# R9A02G021 register map
Vendor: Renesas Electronics Corporation; Series: RISC-V; File version: 1.10.00 + 202304131714_CPU
CPU: other r0p0, little endian, no MPU, no FPU, VTOR, 4 interrupt priority bits, 32 interrupts
Registers are 8-bit, read-write, reset 0x0 unless marked. A register's access mark holds for its fields unless they carry their own. Offsets are from the block's base; [hi:lo] are bit positions; {n}, {i} and the like mark numbered series.

## FLCN — Flash I/O Registers
Base 0x407EC000
0x90 DFLCTL — Data Flash Control Register
  [0] DFLEN — Data Flash Access Enable
    0=Access to the data flash is disabled; 1=Access to the data flash is enabled
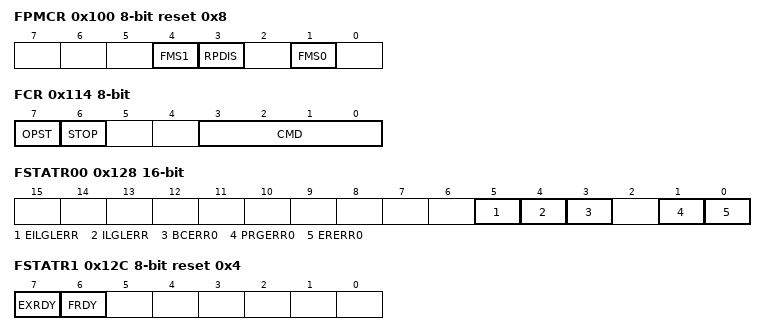
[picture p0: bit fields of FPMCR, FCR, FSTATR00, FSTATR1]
0x100 FPMCR reset 0x8 — Flash P/E Mode Control Register
  [4] FMS1 — Flash Operating Mode Select 1
  [3] RPDIS — Code Flash P/E Disable
    0=Programming of the code flash is enabled; 1=Programming of the code flash is disabled
  [1] FMS0 — Flash Operating Mode Select 0
    0=FMS1 = 0: Read mode FMS1 = 1: Data flash P/E mode; 1=FMS1 = 0: Code flash P/E mode FMS1 = 1: Setting prohibited
0x104 FASR — Flash Area Select Register
  [0] EXS — Extra Area Select
    0=User area or data area; 1=Extra area
0x108 FSARL 16-bit — Flash Processing Start Address Register L
  [15:0] FSARL — Flash Processing Start Address L
0x110 FSARH 16-bit — Flash Processing Start Address Register H
  [15:0] FSARH — Flash Processing Start Address H
0x114 FCR — Flash Control Register
  [7] OPST — Processing Start
    0=Processing stops; 1=Processing starts
  [6] STOP — Forced Processing Stop
  [3:0] CMD — Software Command Setting
    1=Program; 3=Blank check (code flash); 4=Block erase; 6=Chip erase; 11=Blank check (data flash); other=Others (Setting prohibited.)
0x118 FEARL 16-bit — Flash Processing End Address Register L
  [15:0] FEARL — Flash Processing End Address L
0x120 FEARH 16-bit — Flash Processing End Address Register H
  [15:0] FEARH — Flash Processing End Address H
0x124 FRESETR — Flash Reset Register
  [0] FRESET — Software reset of the registers
    0=The registers related to the flash programming are not reset; 1=The registers related to the flash programming are reset
0x128 FSTATR00 16-bit ro — Flash Status Register 0
  [5] EILGLERR — Extra Area Illegal Command Error Flag
    0=No illegal command or illegal access to the extra area is detected; 1=An illegal command or illegal access to the extra area is detected
  [4] ILGLERR — Illegal Command Error Flag
    0=No illegal software command or illegal access is detected; 1=An illegal command or illegal access is detected
  [3] BCERR0 — Blank Check Error Flag 0
    0=Blank checking terminates normally; 1=An error occurs during blank checking
  [1] PRGERR0 — Program Error Flag 0
    0=Programming terminates normally; 1=An error occurs during programming
  [0] ERERR0 — Erase Error Flag 0
    0=Erasure terminates normally; 1=An error occurs during erasure
0x12C FSTATR1 ro reset 0x4 — Flash Status Register 1
  [7] EXRDY — Extra Area Ready Flag
    0=The software command of the FEXCR register is not terminated; 1=The software command of the FEXCR register is terminated
  [6] FRDY — Flash Ready Flag
    0=The software command of the FCR register is not terminated; 1=The software command of the FCR register is terminated
0x130 FWBL0 16-bit — Flash Write Buffer Register L0
  [15:0] WDATA — Flash Write Buffer L0
0x138 FWBH0 16-bit — Flash Write Buffer Register H0
  [15:0] WDATA — Flash Write Buffer H0
0x140 FWBL1 16-bit — Flash Write Buffer Register L1
  [15:0] WDATA — Flash Write Buffer L1 Bits [47:32]
0x144 FWBH1 16-bit — Flash Write Buffer Register H1
  [15:0] WDATA — Flash Write Buffer L1 Bits [63:48]
0x180 FPR reset not defined — Protection Unlock Register
  [7:0] FPR — Protection Unlock
0x184 FPSR ro — Protection Unlock Status Register
  [0] PERR — Protect Error Flag
    0=No error; 1=An error occurs
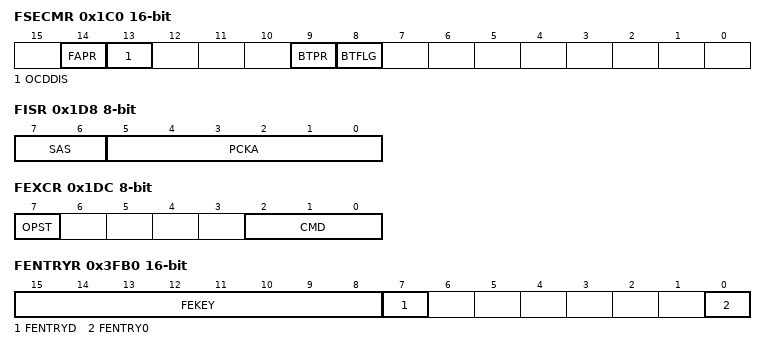
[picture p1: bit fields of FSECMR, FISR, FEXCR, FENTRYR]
0x1C0 FSECMR 16-bit ro — Flash Protection Flag Monitor Register
  [14] FAPR — Access Window Protection Flag
    0=Access window setting is locked; 1=Access window setting is not locked
  [13] OCDDIS — On-Chip Debugger Connection Disable Flag
    0=On-chip debugger connection disabled; 1=On-chip debugger connection enabled
  [9] BTPR — Startup Area Select Protection Flag
    0=Startup area select setting is locked; 1=Startup area select setting is not locked
  [8] BTFLG — Startup Area Select Protection Flag
    0=Startup area is the alternate block (block 1); 1=Startup area is the alternate block (block 0)
0x1C8 FAWSMR 16-bit ro (reset mask 0xF800) — Flash Access Window Start Address Monitor Register
  [10:0] FAWS — Access Window Start Address
0x1D0 FAWEMR 16-bit ro (reset mask 0xF800) — Flash Access Window End Address Monitor Register
  [10:0] FAWE — Access Window End Address
0x1D8 FISR — Flash Initial Setting Register
  [7:6] SAS — Startup Area Select
    2=The startup area is switched to the default area temporarily; 3=The startup area is switched to the alternate area temporarily; other=Others (The startup area is selected according to the settings of the extra area.)
  [5:0] PCKA — Flash-IF Clock Notification
0x1DC FEXCR — Flash Extra Area Control Register
  [7] OPST — Processing Start
    0=Processing stops; 1=Processing starts
  [2:0] CMD — Software Command Setting
    1=Protection setting; 2=Access window information program; {v}=User ID{v-2} program (v=3..6); other=Others (Setting prohibited)
0x1E0 FEAML 16-bit — Flash Error Address Monitor Register L
0x1E8 FEAMH 16-bit — Flash Error Address Monitor Register H
0x228 TSCDR 32-bit ro — Temperature Sensor Calibration Data Register
  [15:0] TSCDR — Temperature Sensor Calibration Data
0x3FB0 FENTRYR 16-bit — Flash P/E Mode Entry Register
  [15:8] FEKEY wo — Key Code
  [7] FENTRYD — Data Flash P/E Mode Entry
    0=The data flash is the read mode; 1=The data flash is the P/E mode
  [0] FENTRY0 — Code Flash P/E Mode Entry 0
    0=The code flash is the read mode; 1=The code flash is the P/E mode
0x3FC4 FLDWAITR — Memory Wait Cycle Control Register for Data Flash
  [0] FLDWAIT1 — Memory Wait Cycle Select for Data Flash
    0=1 wait access (Default); 1=2 wait access
0x3FC8 PFBER — Prefetch Buffer Enable Register
  [0] PFBE — Prefetch Buffer Enable bit
    0=Prefetch buffer is disabled; 1=Prefetch buffer is enabled
